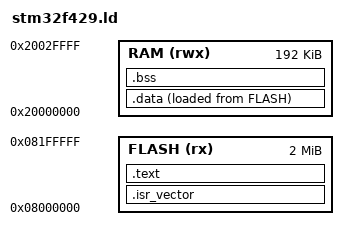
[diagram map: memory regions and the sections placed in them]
MEMORY
{
    FLASH (rx)  : ORIGIN = 0x08000000, LENGTH = 2048K
    RAM   (rwx) : ORIGIN = 0x20000000, LENGTH = 192K
}

_estack = ORIGIN(RAM) + LENGTH(RAM);
_sidata = LOADADDR(.data);

SECTIONS
{
    .isr_vector : {
        KEEP(*(.isr_vector))
    } > FLASH

    .text : {
        *(.text*)
        *(.rodata*)
    } > FLASH

    .data : ALIGN(4) {
        _sdata = .;
        *(.data*)
        . = ALIGN(4);
        _edata = .;
    } > RAM AT> FLASH
    
    .bss : ALIGN(4) {
        _sbss = .;
        *(.bss*)
        *(COMMON)
        . = ALIGN(4);
        _ebss = .;
    } > RAM
}
